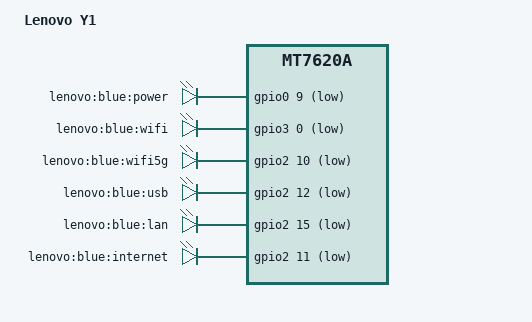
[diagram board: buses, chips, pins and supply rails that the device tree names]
/dts-v1/;

/include/ "Y1.dtsi"

/ {
	compatible = "lenovo,Y1", "ralink,mt7620a-soc";
	model = "Lenovo Y1";

	ethernet@10100000 {
		pinctrl-names = "default";
		pinctrl-0 = <&ephy_pins>;
		mtd-mac-address = <&factory 0x4>;
		ralink,port-map = "llllw";
	};
	
	gpio-leds {
		compatible = "gpio-leds";
		power1 {
			label = "lenovo:blue:power";
			gpios = <&gpio0 9 1>;
		};
		wlan1 {
			label = "lenovo:blue:wifi";
			gpios = <&gpio3 0 1>;
		};
		wlan2 {
			label = "lenovo:blue:wifi5g";
			gpios = <&gpio2 10 1>;
		};
		usb {
			label = "lenovo:blue:usb";
			gpios = <&gpio2 12 1>;
		};
		lan {
			label = "lenovo:blue:lan";
			gpios = <&gpio2 15 1>;
		};
		internet {
			label = "lenovo:blue:internet";
			gpios = <&gpio2 11 1>;
		};
	};
};
